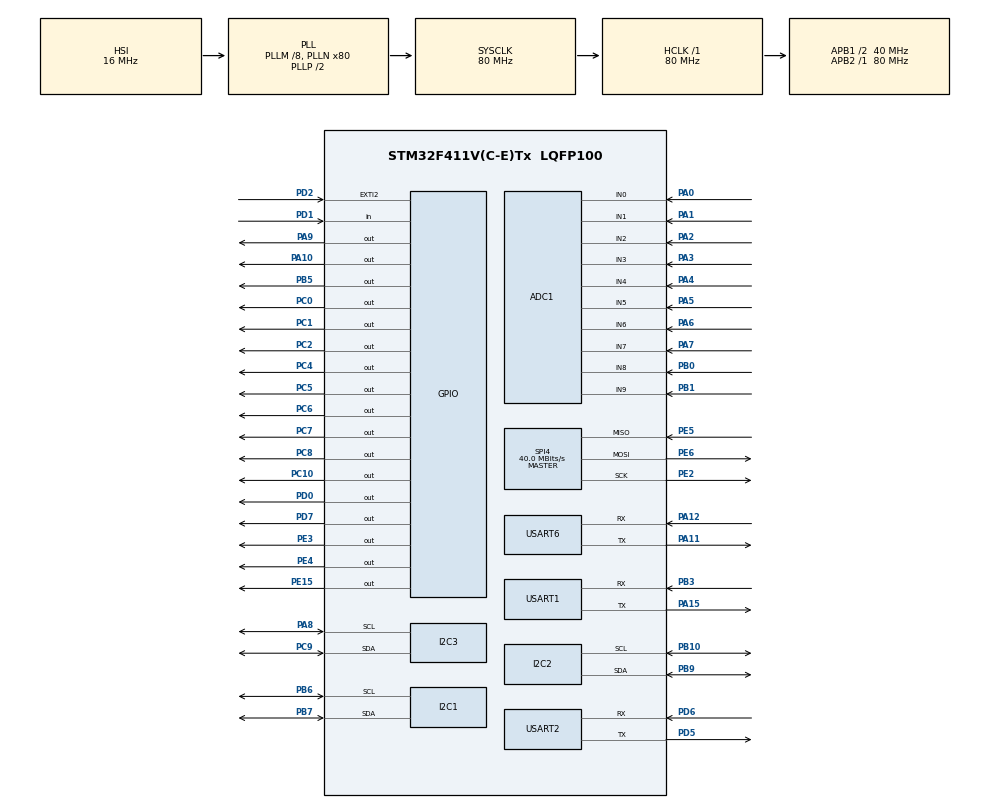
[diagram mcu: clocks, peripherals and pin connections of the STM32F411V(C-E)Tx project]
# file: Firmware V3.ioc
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ADC1.Channel-0\#ChannelRegularConversion=ADC_CHANNEL_0
ADC1.NbrOfConversionFlag=1
ADC1.Rank-0\#ChannelRegularConversion=1
ADC1.SamplingTime-0\#ChannelRegularConversion=ADC_SAMPLETIME_3CYCLES
ADC1.master=1
Dma.Request0=USART2_RX
Dma.Request1=USART6_RX
Dma.Request2=USART1_RX
Dma.USART1_RX.2.Direction=DMA_PERIPH_TO_MEMORY
Dma.USART1_RX.2.FIFOMode=DMA_FIFOMODE_DISABLE
Dma.USART1_RX.2.Instance=DMA2_Stream2
Dma.USART1_RX.2.MemDataAlignment=DMA_MDATAALIGN_BYTE
Dma.USART1_RX.2.MemInc=DMA_MINC_ENABLE
Dma.USART1_RX.2.Mode=DMA_CIRCULAR
Dma.USART1_RX.2.PeriphDataAlignment=DMA_PDATAALIGN_BYTE
Dma.USART1_RX.2.PeriphInc=DMA_PINC_DISABLE
Dma.USART1_RX.2.Priority=DMA_PRIORITY_LOW
Dma.USART2_RX.0.Direction=DMA_PERIPH_TO_MEMORY
Dma.USART2_RX.0.FIFOMode=DMA_FIFOMODE_DISABLE
Dma.USART2_RX.0.Instance=DMA1_Stream5
Dma.USART2_RX.0.MemDataAlignment=DMA_MDATAALIGN_BYTE
Dma.USART2_RX.0.MemInc=DMA_MINC_ENABLE
Dma.USART2_RX.0.Mode=DMA_CIRCULAR
Dma.USART2_RX.0.PeriphDataAlignment=DMA_PDATAALIGN_BYTE
Dma.USART2_RX.0.PeriphInc=DMA_PINC_DISABLE
Dma.USART2_RX.0.Priority=DMA_PRIORITY_LOW
Dma.USART6_RX.1.Direction=DMA_PERIPH_TO_MEMORY
Dma.USART6_RX.1.FIFOMode=DMA_FIFOMODE_DISABLE
Dma.USART6_RX.1.Instance=DMA2_Stream1
Dma.USART6_RX.1.MemDataAlignment=DMA_MDATAALIGN_BYTE
Dma.USART6_RX.1.MemInc=DMA_MINC_ENABLE
Dma.USART6_RX.1.Mode=DMA_CIRCULAR
Dma.USART6_RX.1.PeriphDataAlignment=DMA_PDATAALIGN_BYTE
Dma.USART6_RX.1.PeriphInc=DMA_PINC_DISABLE
Dma.USART6_RX.1.Priority=DMA_PRIORITY_LOW
Mcu.Family=STM32F4
Mcu.Name=STM32F411V(C-E)Tx
Mcu.Package=LQFP100
NVIC.DMA1_Stream5_IRQn=true\:0\:0\:false\:false\:true\:false
NVIC.DMA2_Stream1_IRQn=true\:0\:0\:false\:false\:true\:false
NVIC.DMA2_Stream2_IRQn=true\:0\:0\:false\:false\:true\:false
NVIC.EXTI2_IRQn=true\:3\:3\:true\:false\:false\:true
NVIC.PriorityGroup=NVIC_PRIORITYGROUP_2
NVIC.RTC_WKUP_IRQn=true\:1\:0\:true\:false\:false\:true
NVIC.TIM3_IRQn=true\:2\:3\:true\:false\:false\:true
NVIC.TIM4_IRQn=true\:2\:2\:true\:false\:false\:true
NVIC.USART1_IRQn=true\:3\:2\:true\:false\:false\:true
NVIC.USART2_IRQn=true\:3\:1\:true\:false\:false\:true
NVIC.USART6_IRQn=true\:2\:0\:true\:false\:false\:true
PA0-WKUP.Signal=ADCx_IN0
PA1.Signal=ADCx_IN1
PA10.Signal=GPIO_Output
PA11.Mode=Asynchronous
PA11.Signal=USART6_TX
PA12.Mode=Asynchronous
PA12.Signal=USART6_RX
PA15.Mode=Asynchronous
PA15.Signal=USART1_TX
PA2.Signal=ADCx_IN2
PA3.Signal=ADCx_IN3
PA4.Signal=ADCx_IN4
PA5.Signal=ADCx_IN5
PA6.Signal=ADCx_IN6
PA7.Signal=ADCx_IN7
PA8.Mode=I2C
PA8.Signal=I2C3_SCL
PA9.Signal=GPIO_Output
PB0.Signal=ADCx_IN8
PB1.Signal=ADCx_IN9
PB10.Mode=I2C
PB10.Signal=I2C2_SCL
PB3.Mode=Asynchronous
PB3.Signal=USART1_RX
PB5.PinState=GPIO_PIN_SET
PB5.Signal=GPIO_Output
PB6.Mode=I2C
PB6.Signal=I2C1_SCL
PB7.Mode=I2C
PB7.Signal=I2C1_SDA
PB9.Mode=I2C
PB9.Signal=I2C2_SDA
PC0.Signal=GPIO_Output
PC1.Signal=GPIO_Output
PC10.PinState=GPIO_PIN_SET
PC10.Signal=GPIO_Output
PC14-OSC32_IN.Mode=LSE-External-Oscillator
PC14-OSC32_IN.Signal=RCC_OSC32_IN
PC15-OSC32_OUT.Mode=LSE-External-Oscillator
PC15-OSC32_OUT.Signal=RCC_OSC32_OUT
PC2.PinState=GPIO_PIN_RESET
PC2.Signal=GPIO_Output
PC4.PinState=GPIO_PIN_SET
PC4.Signal=GPIO_Output
PC5.PinState=GPIO_PIN_RESET
PC5.Signal=GPIO_Output
PC6.PinState=GPIO_PIN_SET
PC6.Signal=GPIO_Output
PC7.Signal=GPIO_Output
PC8.Signal=GPIO_Output
PC9.Mode=I2C
PC9.Signal=I2C3_SDA
PD0.PinState=GPIO_PIN_SET
PD0.Signal=GPIO_Output
PD1.Signal=GPIO_Input
PD2.GPIO_ModeDefaultEXTI=GPIO_MODE_IT_RISING_FALLING
PD2.Signal=GPXTI2
PD5.Mode=Asynchronous
PD5.Signal=USART2_TX
PD6.Mode=Asynchronous
PD6.Signal=USART2_RX
PD7.Signal=GPIO_Output
PE15.Signal=GPIO_Output
PE2.Mode=Full_Duplex_Master
PE2.Signal=SPI4_SCK
PE3.PinState=GPIO_PIN_SET
PE3.Signal=GPIO_Output
PE4.Signal=GPIO_Output
PE5.Mode=Full_Duplex_Master
PE5.Signal=SPI4_MISO
PE6.Mode=Full_Duplex_Master
PE6.Signal=SPI4_MOSI
PH0\ -\ OSC_IN.Mode=HSE-External-Oscillator
PH0\ -\ OSC_IN.Signal=RCC_OSC_IN
PH1\ -\ OSC_OUT.Mode=HSE-External-Oscillator
PH1\ -\ OSC_OUT.Signal=RCC_OSC_OUT
ProjectManager.HeapSize=0x200
ProjectManager.StackSize=0x400
ProjectManager.TargetToolchain=MDK-ARM V5
RCC.48MHZClocksFreq_Value=40000000
RCC.AHBFreq_Value=80000000
RCC.APB1CLKDivider=RCC_HCLK_DIV2
RCC.APB1Freq_Value=40000000
RCC.APB1TimFreq_Value=80000000
RCC.APB2Freq_Value=80000000
RCC.APB2TimFreq_Value=80000000
RCC.CortexFreq_Value=80000000
RCC.HCLKFreq_Value=80000000
RCC.HSE_VALUE=8000000
RCC.HSI_VALUE=16000000
RCC.PLLM=8
RCC.PLLN=80
RCC.RCC_RTC_Clock_Source=RCC_RTCCLKSOURCE_LSE
RCC.RCC_RTC_Clock_SourceVirtual=RCC_RTCCLKSOURCE_LSE
RCC.SYSCLKFreq_VALUE=80000000
RCC.SYSCLKSource=RCC_SYSCLKSOURCE_PLLCLK
RCC.VCOOutputFreq_Value=160000000
RTC.WakeUpClock=RTC_WAKEUPCLOCK_CK_SPRE_16BITS
SH.ADCx_IN0.0=ADC1_IN0,IN0
SH.ADCx_IN1.0=ADC1_IN1,IN1
SH.ADCx_IN2.0=ADC1_IN2,IN2
SH.ADCx_IN3.0=ADC1_IN3,IN3
SH.ADCx_IN4.0=ADC1_IN4,IN4
SH.ADCx_IN5.0=ADC1_IN5,IN5
SH.ADCx_IN6.0=ADC1_IN6,IN6
SH.ADCx_IN7.0=ADC1_IN7,IN7
SH.ADCx_IN8.0=ADC1_IN8,IN8
SH.ADCx_IN9.0=ADC1_IN9,IN9
SPI4.CalculateBaudRate=40.0 MBits/s
SPI4.Direction=SPI_DIRECTION_2LINES
SPI4.Mode=SPI_MODE_MASTER
SPI4.VirtualType=VM_MASTER
TIM3.Period=199
TIM3.Prescaler=39999
TIM4.Period=99
TIM4.Prescaler=39999
USART1.VirtualMode=VM_ASYNC
USART2.VirtualMode=VM_ASYNC
USART6.VirtualMode=VM_ASYNC
VP_ADC1_TempSens_Input.Mode=IN-TempSens
VP_RTC_VS_RTC_Activate.Mode=RTC_Enabled
VP_RTC_VS_RTC_Calendar.Mode=RTC_Calendar
VP_RTC_VS_RTC_WakeUp_intern.Mode=WakeUp
VP_TIM3_VS_ClockSourceINT.Mode=Internal
VP_TIM4_VS_ClockSourceINT.Mode=Internal
board=Firmware V3

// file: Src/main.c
/**
  ******************************************************************************
  * File Name          : main.c
  * Description        : Main program body
  ******************************************************************************
  ** This notice applies to any and all portions of this file
  * that are not between comment pairs USER CODE BEGIN and
  * USER CODE END. Other portions of this file, whether
  * inserted by the user or by software development tools
  * are owned by their respective copyright owners.
  *
  * COPYRIGHT(c) 2026 STMicroelectronics
  *
  * Redistribution and use in source and binary forms, with or without modification,
  * are permitted provided that the following conditions are met:
  *   1. Redistributions of source code must retain the above copyright notice,
  *      this list of conditions and the following disclaimer.
  *   2. Redistributions in binary form must reproduce the above copyright notice,
  *      this list of conditions and the following disclaimer in the documentation
  *      and/or other materials provided with the distribution.
  *   3. Neither the name of STMicroelectronics nor the names of its contributors
  *      may be used to endorse or promote products derived from this software
  *      without specific prior written permission.
  *
  * THIS SOFTWARE IS PROVIDED BY THE COPYRIGHT HOLDERS AND CONTRIBUTORS "AS IS"
  * AND ANY EXPRESS OR IMPLIED WARRANTIES, INCLUDING, BUT NOT LIMITED TO, THE
  * IMPLIED WARRANTIES OF MERCHANTABILITY AND FITNESS FOR A PARTICULAR PURPOSE ARE
  * DISCLAIMED. IN NO EVENT SHALL THE COPYRIGHT HOLDER OR CONTRIBUTORS BE LIABLE
  * FOR ANY DIRECT, INDIRECT, INCIDENTAL, SPECIAL, EXEMPLARY, OR CONSEQUENTIAL
  * DAMAGES (INCLUDING, BUT NOT LIMITED TO, PROCUREMENT OF SUBSTITUTE GOODS OR
  * SERVICES; LOSS OF USE, DATA, OR PROFITS; OR BUSINESS INTERRUPTION) HOWEVER
  * CAUSED AND ON ANY THEORY OF LIABILITY, WHETHER IN CONTRACT, STRICT LIABILITY,
  * OR TORT (INCLUDING NEGLIGENCE OR OTHERWISE) ARISING IN ANY WAY OUT OF THE USE
  * OF THIS SOFTWARE, EVEN IF ADVISED OF THE POSSIBILITY OF SUCH DAMAGE.
  *
  ******************************************************************************
  */

#include "main.h"
#include "stm32f4xx_hal.h"

/* USER CODE BEGIN Includes */
#include "prototipi.h"
/* USER CODE END Includes */

ADC_HandleTypeDef hadc1;

I2C_HandleTypeDef hi2c1;
I2C_HandleTypeDef hi2c2;
I2C_HandleTypeDef hi2c3;

RTC_HandleTypeDef hrtc;
RTC_TimeTypeDef sTime;
RTC_DateTypeDef sDate;

SPI_HandleTypeDef hspi4;

TIM_HandleTypeDef htim3;
TIM_HandleTypeDef htim4;

UART_HandleTypeDef huart1;
UART_HandleTypeDef huart2;
UART_HandleTypeDef huart6;
DMA_HandleTypeDef hdma_usart1_rx;
DMA_HandleTypeDef hdma_usart2_rx;
DMA_HandleTypeDef hdma_usart6_rx;

/* USER CODE BEGIN PV */
/* Private variables ---------------------------------------------------------*/

/* USER CODE END PV */

void SystemClock_Config(void);
static void MX_GPIO_Init(void);
static void MX_DMA_Init(void);
static void MX_ADC1_Init(void);
static void MX_RTC_Init(void);
static void MX_I2C1_Init(void);
static void MX_I2C2_Init(void);
static void MX_I2C3_Init(void);
static void MX_SPI4_Init(void);
static void MX_TIM3_Init(void);
static void MX_TIM4_Init(void);
static void MX_USART1_UART_Init(void);
static void MX_USART2_UART_Init(void);
static void MX_USART6_UART_Init(void);

/* USER CODE BEGIN PFP */
/* Private function prototypes -----------------------------------------------*/

/* USER CODE END PFP */

int main(void)
{

  /* MCU Configuration----------------------------------------------------------*/

  /* Reset of all peripherals, Initializes the Flash interface and the Systick. */
  HAL_Init();

  /* Configure the system clock */
  SystemClock_Config();

  /* Initialize all configured peripherals */
  MX_GPIO_Init();
  MX_DMA_Init();
  MX_ADC1_Init();
  MX_RTC_Init();
  MX_I2C1_Init();
  MX_I2C2_Init();
  MX_I2C3_Init();
  MX_SPI4_Init();
  MX_TIM3_Init();
  MX_TIM4_Init();
  MX_USART1_UART_Init();
  MX_USART2_UART_Init();
  MX_USART6_UART_Init();

  /* USER CODE BEGIN 2 */

	mymain();
  /* USER CODE END 2 */

  /* Infinite loop */
  while (1)
  {

  }

}

/** System Clock Configuration
*/
void SystemClock_Config(void)
{

  RCC_OscInitTypeDef RCC_OscInitStruct;
  RCC_ClkInitTypeDef RCC_ClkInitStruct;
  RCC_PeriphCLKInitTypeDef PeriphClkInitStruct;

    /**Configure the main internal regulator output voltage
    */
  __HAL_RCC_PWR_CLK_ENABLE();

  __HAL_PWR_VOLTAGESCALING_CONFIG(PWR_REGULATOR_VOLTAGE_SCALE1);

    /**Initializes the CPU, AHB and APB busses clocks
    */
  RCC_OscInitStruct.OscillatorType = RCC_OSCILLATORTYPE_HSI|RCC_OSCILLATORTYPE_LSE;
  RCC_OscInitStruct.LSEState = RCC_LSE_ON;
  RCC_OscInitStruct.HSIState = RCC_HSI_ON;
  RCC_OscInitStruct.HSICalibrationValue = 16;
  RCC_OscInitStruct.PLL.PLLState = RCC_PLL_ON;
  RCC_OscInitStruct.PLL.PLLSource = RCC_PLLSOURCE_HSI;
  RCC_OscInitStruct.PLL.PLLM = 8;
  RCC_OscInitStruct.PLL.PLLN = 80;
  RCC_OscInitStruct.PLL.PLLP = RCC_PLLP_DIV2;
  RCC_OscInitStruct.PLL.PLLQ = 4;
  if (HAL_RCC_OscConfig(&RCC_OscInitStruct) != HAL_OK)
  {
    _Error_Handler(__FILE__, __LINE__);
  }

    /**Initializes the CPU, AHB and APB busses clocks
    */
  RCC_ClkInitStruct.ClockType = RCC_CLOCKTYPE_HCLK|RCC_CLOCKTYPE_SYSCLK
                              |RCC_CLOCKTYPE_PCLK1|RCC_CLOCKTYPE_PCLK2;
  RCC_ClkInitStruct.SYSCLKSource = RCC_SYSCLKSOURCE_PLLCLK;
  RCC_ClkInitStruct.AHBCLKDivider = RCC_SYSCLK_DIV1;
  RCC_ClkInitStruct.APB1CLKDivider = RCC_HCLK_DIV2;
  RCC_ClkInitStruct.APB2CLKDivider = RCC_HCLK_DIV1;

  if (HAL_RCC_ClockConfig(&RCC_ClkInitStruct, FLASH_LATENCY_2) != HAL_OK)
  {
    _Error_Handler(__FILE__, __LINE__);
  }

  PeriphClkInitStruct.PeriphClockSelection = RCC_PERIPHCLK_RTC;
  PeriphClkInitStruct.RTCClockSelection = RCC_RTCCLKSOURCE_LSE;
  if (HAL_RCCEx_PeriphCLKConfig(&PeriphClkInitStruct) != HAL_OK)
  {
    _Error_Handler(__FILE__, __LINE__);
  }

    /**Configure the Systick interrupt time
    */
  HAL_SYSTICK_Config(HAL_RCC_GetHCLKFreq()/1000);

    /**Configure the Systick
    */
  HAL_SYSTICK_CLKSourceConfig(SYSTICK_CLKSOURCE_HCLK);

  /* SysTick_IRQn interrupt configuration */
  HAL_NVIC_SetPriority(SysTick_IRQn, 0, 0);
}

/* ADC1 init function */
static void MX_ADC1_Init(void)
{

  ADC_ChannelConfTypeDef sConfig;

    /**Configure the global features of the ADC (Clock, Resolution, Data Alignment and number of conversion)
    */
  hadc1.Instance = ADC1;
  hadc1.Init.ClockPrescaler = ADC_CLOCK_SYNC_PCLK_DIV4;
  hadc1.Init.Resolution = ADC_RESOLUTION_12B;
  hadc1.Init.ScanConvMode = DISABLE;
  hadc1.Init.ContinuousConvMode = DISABLE;
  hadc1.Init.DiscontinuousConvMode = DISABLE;
  hadc1.Init.ExternalTrigConvEdge = ADC_EXTERNALTRIGCONVEDGE_NONE;
  hadc1.Init.ExternalTrigConv = ADC_SOFTWARE_START;
  hadc1.Init.DataAlign = ADC_DATAALIGN_RIGHT;
  hadc1.Init.NbrOfConversion = 1;
  hadc1.Init.DMAContinuousRequests = DISABLE;
  hadc1.Init.EOCSelection = ADC_EOC_SINGLE_CONV;
  if (HAL_ADC_Init(&hadc1) != HAL_OK)
  {
    _Error_Handler(__FILE__, __LINE__);
  }

    /**Configure for the selected ADC regular channel its corresponding rank in the sequencer and its sample time.
    */
  sConfig.Channel = ADC_CHANNEL_0;
  sConfig.Rank = 1;
  sConfig.SamplingTime = ADC_SAMPLETIME_3CYCLES;
  if (HAL_ADC_ConfigChannel(&hadc1, &sConfig) != HAL_OK)
  {
    _Error_Handler(__FILE__, __LINE__);
  }

}

/* I2C1 init function */
static void MX_I2C1_Init(void)
{

  hi2c1.Instance = I2C1;
  hi2c1.Init.ClockSpeed = 100000;
  hi2c1.Init.DutyCycle = I2C_DUTYCYCLE_2;
  hi2c1.Init.OwnAddress1 = 0;
  hi2c1.Init.AddressingMode = I2C_ADDRESSINGMODE_7BIT;
  hi2c1.Init.DualAddressMode = I2C_DUALADDRESS_DISABLE;
  hi2c1.Init.OwnAddress2 = 0;
  hi2c1.Init.GeneralCallMode = I2C_GENERALCALL_DISABLE;
  hi2c1.Init.NoStretchMode = I2C_NOSTRETCH_DISABLE;
  if (HAL_I2C_Init(&hi2c1) != HAL_OK)
  {
    _Error_Handler(__FILE__, __LINE__);
  }

}

/* I2C2 init function */
static void MX_I2C2_Init(void)
{

  hi2c2.Instance = I2C2;
  hi2c2.Init.ClockSpeed = 100000;
  hi2c2.Init.DutyCycle = I2C_DUTYCYCLE_2;
  hi2c2.Init.OwnAddress1 = 0;
  hi2c2.Init.AddressingMode = I2C_ADDRESSINGMODE_7BIT;
  hi2c2.Init.DualAddressMode = I2C_DUALADDRESS_DISABLE;
  hi2c2.Init.OwnAddress2 = 0;
  hi2c2.Init.GeneralCallMode = I2C_GENERALCALL_DISABLE;
  hi2c2.Init.NoStretchMode = I2C_NOSTRETCH_DISABLE;
  if (HAL_I2C_Init(&hi2c2) != HAL_OK)
  {
    _Error_Handler(__FILE__, __LINE__);
  }

}

/* I2C3 init function */
static void MX_I2C3_Init(void)
{

  hi2c3.Instance = I2C3;
  hi2c3.Init.ClockSpeed = 100000;
  hi2c3.Init.DutyCycle = I2C_DUTYCYCLE_2;
  hi2c3.Init.OwnAddress1 = 0;
  hi2c3.Init.AddressingMode = I2C_ADDRESSINGMODE_7BIT;
  hi2c3.Init.DualAddressMode = I2C_DUALADDRESS_DISABLE;
  hi2c3.Init.OwnAddress2 = 0;
  hi2c3.Init.GeneralCallMode = I2C_GENERALCALL_DISABLE;
  hi2c3.Init.NoStretchMode = I2C_NOSTRETCH_DISABLE;
  if (HAL_I2C_Init(&hi2c3) != HAL_OK)
  {
    _Error_Handler(__FILE__, __LINE__);
  }

}

/* RTC init function */
static void MX_RTC_Init(void)
{

    /**Initialize RTC Only
    */
  hrtc.Instance = RTC;
  hrtc.Init.HourFormat = RTC_HOURFORMAT_24;
  hrtc.Init.AsynchPrediv = 127;
  hrtc.Init.SynchPrediv = 255;
  hrtc.Init.OutPut = RTC_OUTPUT_DISABLE;
  hrtc.Init.OutPutPolarity = RTC_OUTPUT_POLARITY_HIGH;
  hrtc.Init.OutPutType = RTC_OUTPUT_TYPE_OPENDRAIN;
  if (HAL_RTC_Init(&hrtc) != HAL_OK)
  {
    _Error_Handler(__FILE__, __LINE__);
  }

    /**Initialize RTC and set the Time and Date
    */
  if(HAL_RTCEx_BKUPRead(&hrtc, RTC_BKP_DR0) != 0x32F2){
  if (HAL_RTC_SetTime(&hrtc, &sTime, RTC_FORMAT_BCD) != HAL_OK)
  {
    _Error_Handler(__FILE__, __LINE__);
  }

  if (HAL_RTC_SetDate(&hrtc, &sDate, RTC_FORMAT_BCD) != HAL_OK)
  {
    _Error_Handler(__FILE__, __LINE__);
  }

    HAL_RTCEx_BKUPWrite(&hrtc,RTC_BKP_DR0,0x32F2);
  }
    /**Enable the WakeUp
    */
  if (HAL_RTCEx_SetWakeUpTimer_IT(&hrtc, 0, RTC_WAKEUPCLOCK_CK_SPRE_16BITS) != HAL_OK)
  {
    _Error_Handler(__FILE__, __LINE__);
  }

}

/* SPI4 init function */
static void MX_SPI4_Init(void)
{

  /* SPI4 parameter configuration*/
  hspi4.Instance = SPI4;
  hspi4.Init.Mode = SPI_MODE_MASTER;
  hspi4.Init.Direction = SPI_DIRECTION_2LINES;
  hspi4.Init.DataSize = SPI_DATASIZE_8BIT;
  hspi4.Init.CLKPolarity = SPI_POLARITY_LOW;
  hspi4.Init.CLKPhase = SPI_PHASE_1EDGE;
  hspi4.Init.NSS = SPI_NSS_SOFT;
  hspi4.Init.BaudRatePrescaler = SPI_BAUDRATEPRESCALER_2;
  hspi4.Init.FirstBit = SPI_FIRSTBIT_MSB;
  hspi4.Init.TIMode = SPI_TIMODE_DISABLE;
  hspi4.Init.CRCCalculation = SPI_CRCCALCULATION_DISABLE;
  hspi4.Init.CRCPolynomial = 10;
  if (HAL_SPI_Init(&hspi4) != HAL_OK)
  {
    _Error_Handler(__FILE__, __LINE__);
  }

}

/* TIM3 init function */
static void MX_TIM3_Init(void)
{

  TIM_ClockConfigTypeDef sClockSourceConfig;
  TIM_MasterConfigTypeDef sMasterConfig;

  htim3.Instance = TIM3;
  htim3.Init.Prescaler = 39999;
  htim3.Init.CounterMode = TIM_COUNTERMODE_UP;
  htim3.Init.Period = 199;
  htim3.Init.ClockDivision = TIM_CLOCKDIVISION_DIV1;
  if (HAL_TIM_Base_Init(&htim3) != HAL_OK)
  {
    _Error_Handler(__FILE__, __LINE__);
  }

  sClockSourceConfig.ClockSource = TIM_CLOCKSOURCE_INTERNAL;
  if (HAL_TIM_ConfigClockSource(&htim3, &sClockSourceConfig) != HAL_OK)
  {
    _Error_Handler(__FILE__, __LINE__);
  }

  sMasterConfig.MasterOutputTrigger = TIM_TRGO_RESET;
  sMasterConfig.MasterSlaveMode = TIM_MASTERSLAVEMODE_DISABLE;
  if (HAL_TIMEx_MasterConfigSynchronization(&htim3, &sMasterConfig) != HAL_OK)
  {
    _Error_Handler(__FILE__, __LINE__);
  }

}

/* TIM4 init function */
static void MX_TIM4_Init(void)
{

  TIM_ClockConfigTypeDef sClockSourceConfig;
  TIM_MasterConfigTypeDef sMasterConfig;

  htim4.Instance = TIM4;
  htim4.Init.Prescaler = 39999;
  htim4.Init.CounterMode = TIM_COUNTERMODE_UP;
  htim4.Init.Period = 99;
  htim4.Init.ClockDivision = TIM_CLOCKDIVISION_DIV1;
  if (HAL_TIM_Base_Init(&htim4) != HAL_OK)
  {
    _Error_Handler(__FILE__, __LINE__);
  }

  sClockSourceConfig.ClockSource = TIM_CLOCKSOURCE_INTERNAL;
  if (HAL_TIM_ConfigClockSource(&htim4, &sClockSourceConfig) != HAL_OK)
  {
    _Error_Handler(__FILE__, __LINE__);
  }

  sMasterConfig.MasterOutputTrigger = TIM_TRGO_RESET;
  sMasterConfig.MasterSlaveMode = TIM_MASTERSLAVEMODE_DISABLE;
  if (HAL_TIMEx_MasterConfigSynchronization(&htim4, &sMasterConfig) != HAL_OK)
  {
    _Error_Handler(__FILE__, __LINE__);
  }

}

/* USART1 init function */
static void MX_USART1_UART_Init(void)
{

  huart1.Instance = USART1;
  huart1.Init.BaudRate = 115200;
  huart1.Init.WordLength = UART_WORDLENGTH_8B;
  huart1.Init.StopBits = UART_STOPBITS_1;
  huart1.Init.Parity = UART_PARITY_NONE;
  huart1.Init.Mode = UART_MODE_TX_RX;
  huart1.Init.HwFlowCtl = UART_HWCONTROL_NONE;
  huart1.Init.OverSampling = UART_OVERSAMPLING_16;
  if (HAL_UART_Init(&huart1) != HAL_OK)
  {
    _Error_Handler(__FILE__, __LINE__);
  }

}

/* USART2 init function */
static void MX_USART2_UART_Init(void)
{

  huart2.Instance = USART2;
  huart2.Init.BaudRate = 115200;
  huart2.Init.WordLength = UART_WORDLENGTH_8B;
  huart2.Init.StopBits = UART_STOPBITS_1;
  huart2.Init.Parity = UART_PARITY_NONE;
  huart2.Init.Mode = UART_MODE_TX_RX;
  huart2.Init.HwFlowCtl = UART_HWCONTROL_NONE;
  huart2.Init.OverSampling = UART_OVERSAMPLING_16;
  if (HAL_UART_Init(&huart2) != HAL_OK)
  {
    _Error_Handler(__FILE__, __LINE__);
  }

}

/* USART6 init function */
static void MX_USART6_UART_Init(void)
{

  huart6.Instance = USART6;
  huart6.Init.BaudRate = 115200;
  huart6.Init.WordLength = UART_WORDLENGTH_8B;
  huart6.Init.StopBits = UART_STOPBITS_1;
  huart6.Init.Parity = UART_PARITY_NONE;
  huart6.Init.Mode = UART_MODE_TX_RX;
  huart6.Init.HwFlowCtl = UART_HWCONTROL_NONE;
  huart6.Init.OverSampling = UART_OVERSAMPLING_16;
  if (HAL_UART_Init(&huart6) != HAL_OK)
  {
    _Error_Handler(__FILE__, __LINE__);
  }

}

static void MX_DMA_Init(void)
{
  /* Init with LL driver */
  /* DMA controller clock enable */
  LL_AHB1_GRP1_EnableClock(LL_AHB1_GRP1_PERIPH_DMA1);
  LL_AHB1_GRP1_EnableClock(LL_AHB1_GRP1_PERIPH_DMA2);

  /* DMA interrupt init */
  /* DMA1_Stream5_IRQn interrupt configuration */
  HAL_NVIC_SetPriority(DMA1_Stream5_IRQn, 0, 0);
  HAL_NVIC_EnableIRQ(DMA1_Stream5_IRQn);
  /* DMA2_Stream1_IRQn interrupt configuration */
  HAL_NVIC_SetPriority(DMA2_Stream1_IRQn, 0, 0);
  HAL_NVIC_EnableIRQ(DMA2_Stream1_IRQn);
  /* DMA2_Stream2_IRQn interrupt configuration */
  HAL_NVIC_SetPriority(DMA2_Stream2_IRQn, 0, 0);
  HAL_NVIC_EnableIRQ(DMA2_Stream2_IRQn);

}

/** Configure pins as
        * Analog
        * Input
        * Output
        * EVENT_OUT
        * EXTI
*/
static void MX_GPIO_Init(void)
{

  GPIO_InitTypeDef GPIO_InitStruct;

  /* GPIO Ports Clock Enable */
  __HAL_RCC_GPIOE_CLK_ENABLE();
  __HAL_RCC_GPIOC_CLK_ENABLE();
  __HAL_RCC_GPIOH_CLK_ENABLE();
  __HAL_RCC_GPIOA_CLK_ENABLE();
  __HAL_RCC_GPIOB_CLK_ENABLE();
  __HAL_RCC_GPIOD_CLK_ENABLE();

  /*Configure GPIO pin Output Level */
  HAL_GPIO_WritePin(GPIOE, GPIO_PIN_3, GPIO_PIN_SET);

  /*Configure GPIO pin Output Level */
  HAL_GPIO_WritePin(GPIOE, GPIO_PIN_4, GPIO_PIN_RESET);

  /*
   * PE15 parte aperto. Viene richiuso dal firmware soltanto dopo il
   * ritardo di avvio, evitando che un reset alimentato dalla sola
   * batteria annulli immediatamente il comando di spegnimento.
   */
  HAL_GPIO_WritePin(GPIOE, GPIO_PIN_15, GPIO_PIN_RESET);

  /*Configure GPIO pin Output Level */
  HAL_GPIO_WritePin(GPIOC, GPIO_PIN_0|GPIO_PIN_1|GPIO_PIN_2|GPIO_PIN_5
                          |GPIO_PIN_7|GPIO_PIN_8, GPIO_PIN_RESET);

  /*Configure GPIO pin Output Level */
  HAL_GPIO_WritePin(GPIOC, GPIO_PIN_4|GPIO_PIN_6|GPIO_PIN_10, GPIO_PIN_SET);

  /*Configure GPIO pin Output Level */
  HAL_GPIO_WritePin(GPIOA, GPIO_PIN_9|GPIO_PIN_10, GPIO_PIN_RESET);

  /*Configure GPIO pin Output Level */
  HAL_GPIO_WritePin(GPIOD, GPIO_PIN_0, GPIO_PIN_SET);

  /*Configure GPIO pin Output Level */
  HAL_GPIO_WritePin(GPIOD, GPIO_PIN_7, GPIO_PIN_RESET);

  /*Configure GPIO pin Output Level */
  HAL_GPIO_WritePin(GPIOB, GPIO_PIN_5, GPIO_PIN_SET);

  /*Configure GPIO pins : PE3 PE4 PE15 */
  GPIO_InitStruct.Pin = GPIO_PIN_3|GPIO_PIN_4|GPIO_PIN_15;
  GPIO_InitStruct.Mode = GPIO_MODE_OUTPUT_PP;
  GPIO_InitStruct.Pull = GPIO_NOPULL;
  GPIO_InitStruct.Speed = GPIO_SPEED_FREQ_LOW;
  HAL_GPIO_Init(GPIOE, &GPIO_InitStruct);

  /*Configure GPIO pins : PC0 PC1 PC2 PC4
                           PC5 PC6 PC7 PC8
                           PC10 */
  GPIO_InitStruct.Pin = GPIO_PIN_0|GPIO_PIN_1|GPIO_PIN_2|GPIO_PIN_4
                          |GPIO_PIN_5|GPIO_PIN_6|GPIO_PIN_7|GPIO_PIN_8
                          |GPIO_PIN_10;
  GPIO_InitStruct.Mode = GPIO_MODE_OUTPUT_PP;
  GPIO_InitStruct.Pull = GPIO_NOPULL;
  GPIO_InitStruct.Speed = GPIO_SPEED_FREQ_LOW;
  HAL_GPIO_Init(GPIOC, &GPIO_InitStruct);

  /*Configure GPIO pins : PA9 PA10 */
  GPIO_InitStruct.Pin = GPIO_PIN_9|GPIO_PIN_10;
  GPIO_InitStruct.Mode = GPIO_MODE_OUTPUT_PP;
  GPIO_InitStruct.Pull = GPIO_NOPULL;
  GPIO_InitStruct.Speed = GPIO_SPEED_FREQ_LOW;
  HAL_GPIO_Init(GPIOA, &GPIO_InitStruct);

  /*Configure GPIO pins : PD0 PD7 */
  GPIO_InitStruct.Pin = GPIO_PIN_0|GPIO_PIN_7;
  GPIO_InitStruct.Mode = GPIO_MODE_OUTPUT_PP;
  GPIO_InitStruct.Pull = GPIO_NOPULL;
  GPIO_InitStruct.Speed = GPIO_SPEED_FREQ_LOW;
  HAL_GPIO_Init(GPIOD, &GPIO_InitStruct);

  /*Configure GPIO pin : PD1 */
  GPIO_InitStruct.Pin = GPIO_PIN_1;
  GPIO_InitStruct.Mode = GPIO_MODE_INPUT;
  GPIO_InitStruct.Pull = GPIO_NOPULL;
  HAL_GPIO_Init(GPIOD, &GPIO_InitStruct);

  /*Configure GPIO pin : PD2 */
  GPIO_InitStruct.Pin = GPIO_PIN_2;
  GPIO_InitStruct.Mode = GPIO_MODE_IT_RISING_FALLING;
  GPIO_InitStruct.Pull = GPIO_NOPULL;
  HAL_GPIO_Init(GPIOD, &GPIO_InitStruct);

  /*Configure GPIO pin : PB5 */
  GPIO_InitStruct.Pin = GPIO_PIN_5;
  GPIO_InitStruct.Mode = GPIO_MODE_OUTPUT_PP;
  GPIO_InitStruct.Pull = GPIO_NOPULL;
  GPIO_InitStruct.Speed = GPIO_SPEED_FREQ_LOW;
  HAL_GPIO_Init(GPIOB, &GPIO_InitStruct);

  /* EXTI interrupt init*/
  HAL_NVIC_SetPriority(EXTI2_IRQn, 3, 3);
  HAL_NVIC_EnableIRQ(EXTI2_IRQn);

}

void _Error_Handler(char * file, int line)
{
  while(1)
  {
  }
}

/************************ (C) COPYRIGHT STMicroelectronics *****END OF FILE****/
